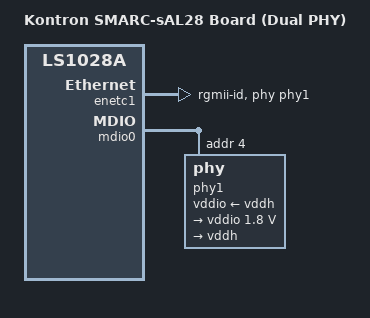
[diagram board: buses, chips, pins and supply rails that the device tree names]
// SPDX-License-Identifier: GPL-2.0+
/*
 * Kontron SMARC-sAL28 device tree source (Dual PHY version)
 */

/dts-v1/;

#include "fsl-ls1028a-kontron-sl28.dts"
#include <dt-bindings/net/qca-ar803x.h>

/ {
	u-boot,dm-pre-reloc;
	model = "Kontron SMARC-sAL28 Board (Dual PHY)";
	compatible = "kontron,sl28-var4", "kontron,sl28", "fsl,ls1028a";
};

&enetc1 {
	status = "okay";
	phy-mode = "rgmii-id";
	phy-handle = <&phy1>;
};

&mdio0 {
	phy1: phy@4 {
		reg = <4>;

		qca,clk-out-frequency = <125000000>;
		qca,clk-out-strength = <AR803X_STRENGTH_FULL>;

		vddio-supply = <&vddh>;

		vddio: vddio-regulator {
			regulator-name = "VDDIO";
			regulator-min-microvolt = <1800000>;
			regulator-max-microvolt = <1800000>;
		};

		vddh: vddh-regulator {
			regulator-name = "VDDH";
		};
	};
};
